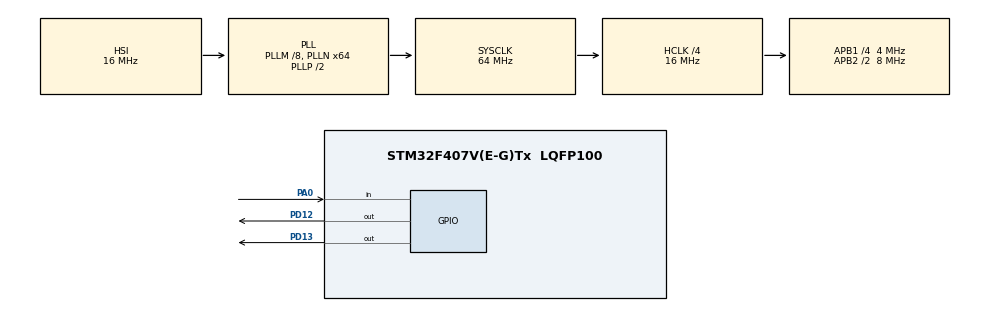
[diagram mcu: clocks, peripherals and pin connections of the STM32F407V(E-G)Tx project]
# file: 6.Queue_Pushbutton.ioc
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Mcu.Family=STM32F4
Mcu.Name=STM32F407V(E-G)Tx
Mcu.Package=LQFP100
NVIC.PriorityGroup=NVIC_PRIORITYGROUP_4
NVIC.TIM6_DAC_IRQn=true\:0\:0\:false\:false\:true\:false\:true\:true
NVIC.TimeBase=TIM6_DAC_IRQn
NVIC.TimeBaseIP=TIM6
PA0-WKUP.Signal=GPIO_Input
PA13.Mode=Serial_Wire
PA13.Signal=SYS_JTMS-SWDIO
PA14.Mode=Serial_Wire
PA14.Signal=SYS_JTCK-SWCLK
PD12.Signal=GPIO_Output
PD13.Signal=GPIO_Output
ProjectManager.HeapSize=0x200
ProjectManager.StackSize=0x400
ProjectManager.TargetToolchain=STM32CubeIDE
RCC.48MHZClocksFreq_Value=18285714.285714287
RCC.AHBCLKDivider=RCC_SYSCLK_DIV4
RCC.AHBFreq_Value=16000000
RCC.APB1CLKDivider=RCC_HCLK_DIV4
RCC.APB1Freq_Value=4000000
RCC.APB1TimFreq_Value=8000000
RCC.APB2CLKDivider=RCC_HCLK_DIV2
RCC.APB2Freq_Value=8000000
RCC.APB2TimFreq_Value=16000000
RCC.CortexFreq_Value=16000000
RCC.HCLKFreq_Value=16000000
RCC.HSE_VALUE=8000000
RCC.HSI_VALUE=16000000
RCC.LSE_VALUE=32768
RCC.PLLM=8
RCC.PLLN=64
RCC.PLLQ=7
RCC.SYSCLKFreq_VALUE=64000000
RCC.SYSCLKSource=RCC_SYSCLKSOURCE_PLLCLK
RCC.VCOOutputFreq_Value=128000000
VP_SYS_VS_tim6.Mode=TIM6
board=STM32F407G-DISC1

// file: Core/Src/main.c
/* USER CODE BEGIN Header */
/**
 ******************************************************************************
 * @file           : main.c
 * @brief          : Main program body
 ******************************************************************************
 * @attention
 *
 * Copyright (c) 2024 STMicroelectronics.
 * All rights reserved.
 *
 * This software is licensed under terms that can be found in the LICENSE file
 * in the root directory of this software component.
 * If no LICENSE file comes with this software, it is provided AS-IS.
 *
 ******************************************************************************
 */
/* USER CODE END Header */
#include "main.h"

/* USER CODE BEGIN Includes */

#include "FreeRTOS.h"
#include "task.h"
#include "queue.h"

/* USER CODE END Includes */

/* USER CODE BEGIN PV */

QueueHandle_t queuehandle;

/* USER CODE END PV */

void SystemClock_Config(void);
static void MX_GPIO_Init(void);

/* USER CODE BEGIN 0 */

void PushButtonTask(void *pvParameters) {
	uint8_t button_press_count = 0;
	uint8_t button_state = 0;
	uint8_t led_state = 0;
	uint8_t last_button_state = 0; // Previous button state

	while (1) {
		button_state = HAL_GPIO_ReadPin(GPIOA, GPIO_PIN_0);
		if (button_state == 1 && last_button_state == 0) {
			button_press_count++; // Increment counter on button press
		}

		last_button_state = button_state;
		if (button_press_count >= 5) {
			led_state = 1;
			xQueueSend(queuehandle, &led_state, portMAX_DELAY);
			button_press_count = 0;
		}
		vTaskDelay(pdMS_TO_TICKS(50)); // Poll every 50ms for debounce

	}
}

void LedTask(void *pvParameters) {
	uint8_t led_state = 0;
	while (1) {
		xQueueReceive(queuehandle, &led_state, portMAX_DELAY);
		if (led_state == 1) {
			for (int i = 0; i < 6; i++) {
				HAL_GPIO_WritePin(GPIOD, GPIO_PIN_12, GPIO_PIN_SET);
				HAL_GPIO_WritePin(GPIOD, GPIO_PIN_13, GPIO_PIN_SET);
				vTaskDelay(pdMS_TO_TICKS(100));
				HAL_GPIO_WritePin(GPIOD, GPIO_PIN_12, GPIO_PIN_RESET);
				HAL_GPIO_WritePin(GPIOD, GPIO_PIN_13, GPIO_PIN_RESET);
				vTaskDelay(pdMS_TO_TICKS(100));
			}

		}
	}
}

/* USER CODE END 0 */

int main(void) {

	/* MCU Configuration--------------------------------------------------------*/

	/* Reset of all peripherals, Initializes the Flash interface and the Systick. */
	HAL_Init();

	/* Configure the system clock */
	SystemClock_Config();

	/* Initialize all configured peripherals */
	MX_GPIO_Init();
	/* USER CODE BEGIN 2 */

	queuehandle = xQueueCreate(1, sizeof(uint8_t));
	if (queuehandle == NULL) {
		// Handle queue creation failure
	}
	xTaskCreate(PushButtonTask, "Push button Task", 100, NULL, 1, NULL);
	xTaskCreate(LedTask, "LED Task", 100, NULL, 1, NULL);
	vTaskStartScheduler();

	/* USER CODE END 2 */

	/* Infinite loop */
	while (1) {

	}
}

void SystemClock_Config(void) {
	RCC_OscInitTypeDef RCC_OscInitStruct = { 0 };
	RCC_ClkInitTypeDef RCC_ClkInitStruct = { 0 };

	/** Configure the main internal regulator output voltage
	 */
	__HAL_RCC_PWR_CLK_ENABLE();
	__HAL_PWR_VOLTAGESCALING_CONFIG(PWR_REGULATOR_VOLTAGE_SCALE1);

	/** Initializes the RCC Oscillators according to the specified parameters
	 * in the RCC_OscInitTypeDef structure.
	 */
	RCC_OscInitStruct.OscillatorType = RCC_OSCILLATORTYPE_HSI;
	RCC_OscInitStruct.HSIState = RCC_HSI_ON;
	RCC_OscInitStruct.HSICalibrationValue = RCC_HSICALIBRATION_DEFAULT;
	RCC_OscInitStruct.PLL.PLLState = RCC_PLL_ON;
	RCC_OscInitStruct.PLL.PLLSource = RCC_PLLSOURCE_HSI;
	RCC_OscInitStruct.PLL.PLLM = 8;
	RCC_OscInitStruct.PLL.PLLN = 64;
	RCC_OscInitStruct.PLL.PLLP = RCC_PLLP_DIV2;
	RCC_OscInitStruct.PLL.PLLQ = 7;
	if (HAL_RCC_OscConfig(&RCC_OscInitStruct) != HAL_OK) {
		Error_Handler();
	}

	/** Initializes the CPU, AHB and APB buses clocks
	 */
	RCC_ClkInitStruct.ClockType = RCC_CLOCKTYPE_HCLK | RCC_CLOCKTYPE_SYSCLK
			| RCC_CLOCKTYPE_PCLK1 | RCC_CLOCKTYPE_PCLK2;
	RCC_ClkInitStruct.SYSCLKSource = RCC_SYSCLKSOURCE_PLLCLK;
	RCC_ClkInitStruct.AHBCLKDivider = RCC_SYSCLK_DIV4;
	RCC_ClkInitStruct.APB1CLKDivider = RCC_HCLK_DIV4;
	RCC_ClkInitStruct.APB2CLKDivider = RCC_HCLK_DIV2;

	if (HAL_RCC_ClockConfig(&RCC_ClkInitStruct, FLASH_LATENCY_0) != HAL_OK) {
		Error_Handler();
	}
}

static void MX_GPIO_Init(void) {
	GPIO_InitTypeDef GPIO_InitStruct = { 0 };

	/* GPIO Ports Clock Enable */
	__HAL_RCC_GPIOA_CLK_ENABLE();
	__HAL_RCC_GPIOD_CLK_ENABLE();

	/*Configure GPIO pin Output Level */
	HAL_GPIO_WritePin(GPIOD, GPIO_PIN_12 | GPIO_PIN_13, GPIO_PIN_RESET);

	/*Configure GPIO pin : PA0 */
	GPIO_InitStruct.Pin = GPIO_PIN_0;
	GPIO_InitStruct.Mode = GPIO_MODE_INPUT;
	GPIO_InitStruct.Pull = GPIO_NOPULL;
	HAL_GPIO_Init(GPIOA, &GPIO_InitStruct);

	/*Configure GPIO pins : PD12 PD13 */
	GPIO_InitStruct.Pin = GPIO_PIN_12 | GPIO_PIN_13;
	GPIO_InitStruct.Mode = GPIO_MODE_OUTPUT_PP;
	GPIO_InitStruct.Pull = GPIO_NOPULL;
	GPIO_InitStruct.Speed = GPIO_SPEED_FREQ_LOW;
	HAL_GPIO_Init(GPIOD, &GPIO_InitStruct);

}

void HAL_TIM_PeriodElapsedCallback(TIM_HandleTypeDef *htim) {
	if (htim->Instance == TIM6) {
		HAL_IncTick();
	}
}

void Error_Handler(void) {
	__disable_irq();
	while (1) {
	}
}
